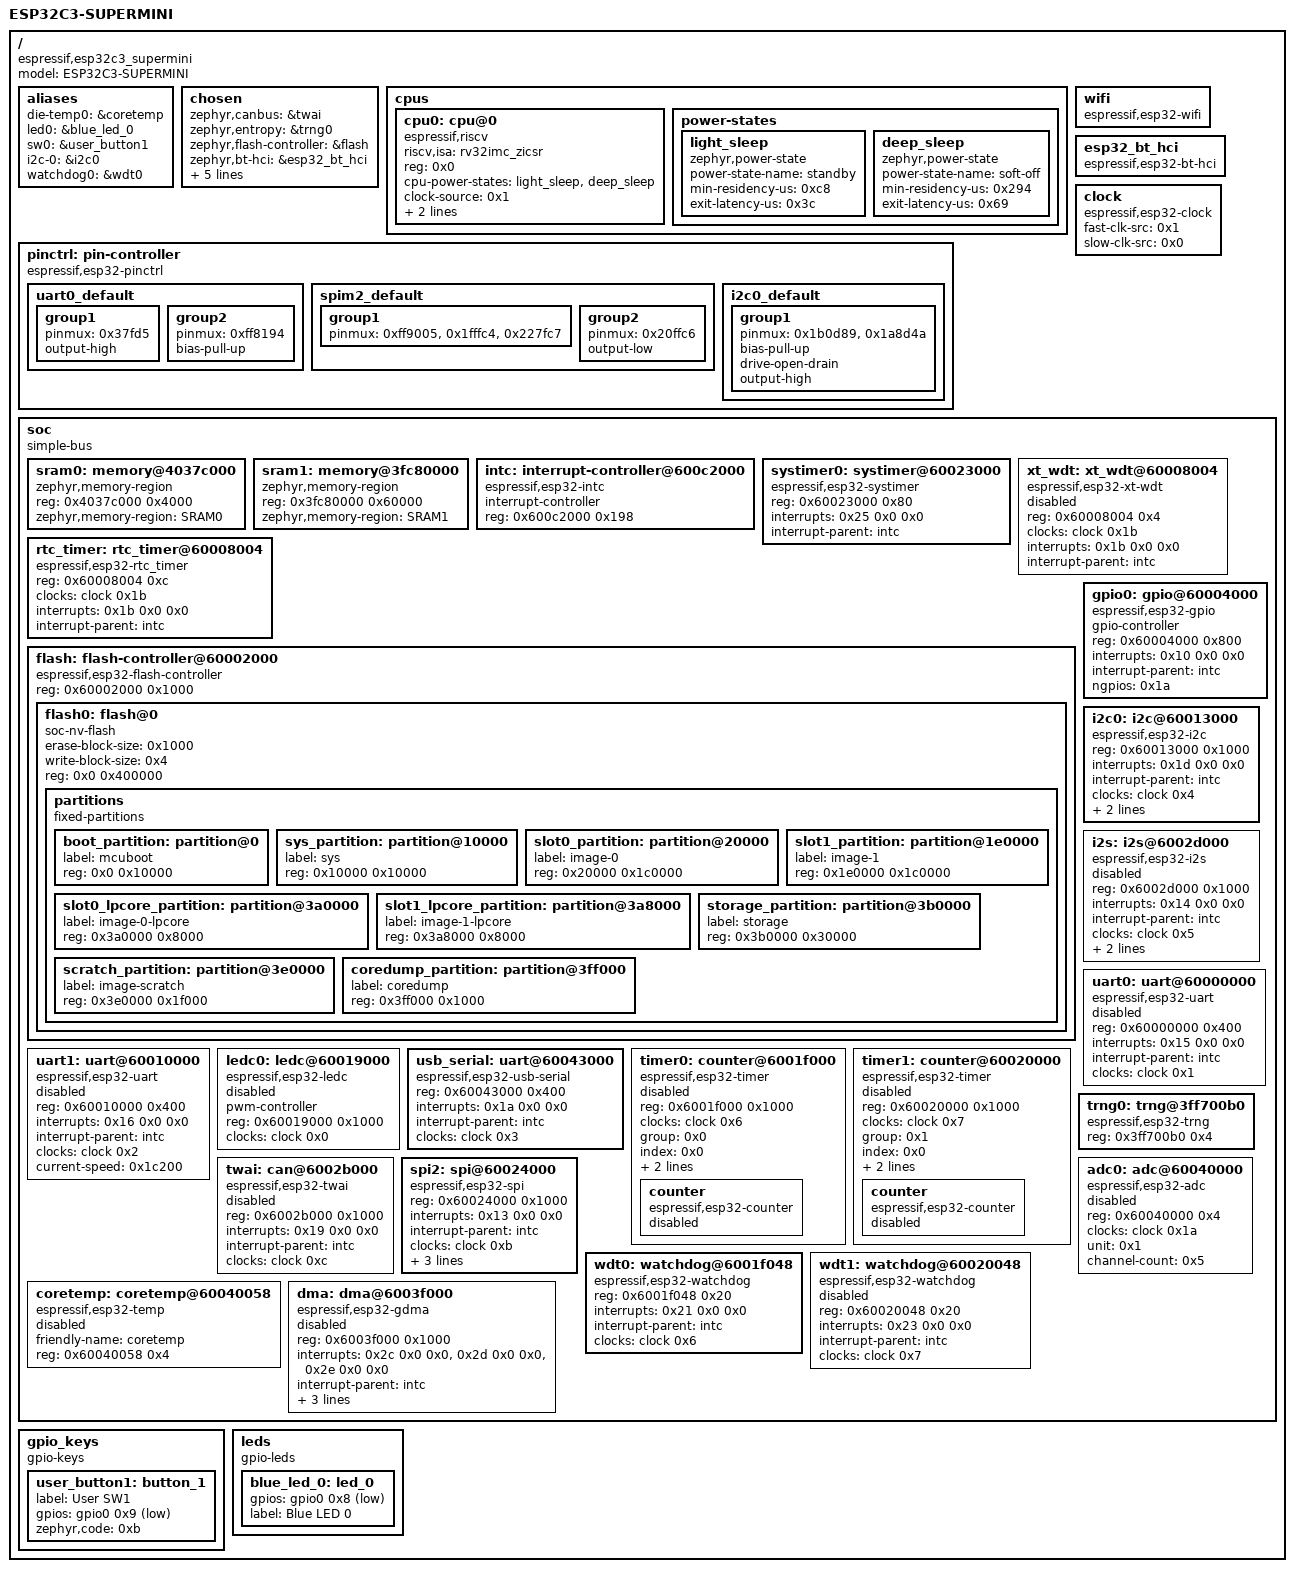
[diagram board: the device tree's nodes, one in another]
/dts-v1/;

/* node '/' defined in zephyr\dts\riscv\espressif\esp32c3\esp32c3_common.dtsi:15 */
/ {
	#address-cells = < 0x1 >;                   /* in zephyr\dts\riscv\espressif\esp32c3\esp32c3_common.dtsi:16 */
	#size-cells = < 0x1 >;                      /* in zephyr\dts\riscv\espressif\esp32c3\esp32c3_common.dtsi:17 */
	model = "ESP32C3-SUPERMINI";                /* in zephyr\boards\others\esp32c3_supermini\esp32c3_supermini.dts:15 */
	compatible = "espressif,esp32c3_supermini"; /* in zephyr\boards\others\esp32c3_supermini\esp32c3_supermini.dts:16 */

	/* node '/aliases' defined in zephyr\dts\riscv\espressif\esp32c3\esp32c3_common.dtsi:19 */
	aliases {
		die-temp0 = &coretemp; /* in zephyr\dts\riscv\espressif\esp32c3\esp32c3_common.dtsi:20 */
		led0 = &blue_led_0;    /* in zephyr\boards\others\esp32c3_supermini\esp32c3_supermini.dts:27 */
		sw0 = &user_button1;   /* in zephyr\boards\others\esp32c3_supermini\esp32c3_supermini.dts:28 */
		i2c-0 = &i2c0;         /* in zephyr\boards\others\esp32c3_supermini\esp32c3_supermini.dts:29 */
		watchdog0 = &wdt0;     /* in zephyr\boards\others\esp32c3_supermini\esp32c3_supermini.dts:30 */
	};

	/* node '/chosen' defined in zephyr\dts\riscv\espressif\esp32c3\esp32c3_common.dtsi:23 */
	chosen {
		zephyr,canbus = &twai;                    /* in zephyr\dts\riscv\espressif\esp32c3\esp32c3_common.dtsi:24 */
		zephyr,entropy = &trng0;                  /* in zephyr\dts\riscv\espressif\esp32c3\esp32c3_common.dtsi:25 */
		zephyr,flash-controller = &flash;         /* in zephyr\dts\riscv\espressif\esp32c3\esp32c3_common.dtsi:26 */
		zephyr,bt-hci = &esp32_bt_hci;            /* in zephyr\dts\riscv\espressif\esp32c3\esp32c3_common.dtsi:27 */
		zephyr,sram = &sram1;                     /* in zephyr\boards\others\esp32c3_supermini\esp32c3_supermini.dts:19 */
		zephyr,console = &usb_serial;             /* in zephyr\boards\others\esp32c3_supermini\esp32c3_supermini.dts:20 */
		zephyr,shell-uart = &usb_serial;          /* in zephyr\boards\others\esp32c3_supermini\esp32c3_supermini.dts:21 */
		zephyr,flash = &flash0;                   /* in zephyr\boards\others\esp32c3_supermini\esp32c3_supermini.dts:22 */
		zephyr,code-partition = &slot0_partition; /* in zephyr\boards\others\esp32c3_supermini\esp32c3_supermini.dts:23 */
	};

	/* node '/cpus' defined in zephyr\dts\riscv\espressif\esp32c3\esp32c3_common.dtsi:30 */
	cpus {
		#address-cells = < 0x1 >; /* in zephyr\dts\riscv\espressif\esp32c3\esp32c3_common.dtsi:31 */
		#size-cells = < 0x0 >;    /* in zephyr\dts\riscv\espressif\esp32c3\esp32c3_common.dtsi:32 */

		/* node '/cpus/cpu@0' defined in zephyr\dts\riscv\espressif\esp32c3\esp32c3_common.dtsi:34 */
		cpu0: cpu@0 {
			device_type = "cpu";                             /* in zephyr\dts\riscv\espressif\esp32c3\esp32c3_common.dtsi:35 */
			compatible = "espressif,riscv",
			             "riscv";                            /* in zephyr\dts\riscv\espressif\esp32c3\esp32c3_common.dtsi:36 */
			riscv,isa = "rv32imc_zicsr";                     /* in zephyr\dts\riscv\espressif\esp32c3\esp32c3_common.dtsi:37 */
			reg = < 0x0 >;                                   /* in zephyr\dts\riscv\espressif\esp32c3\esp32c3_common.dtsi:38 */
			cpu-power-states = < &light_sleep &deep_sleep >; /* in zephyr\dts\riscv\espressif\esp32c3\esp32c3_common.dtsi:39 */
			clock-source = < 0x1 >;                          /* in zephyr\dts\riscv\espressif\esp32c3\esp32c3_common.dtsi:40 */
			clock-frequency = < 0x9896800 >;                 /* in zephyr\dts\riscv\espressif\esp32c3\esp32c3_common.dtsi:41 */
			xtal-freq = < 0x2625a00 >;                       /* in zephyr\dts\riscv\espressif\esp32c3\esp32c3_common.dtsi:42 */
		};

		/* node '/cpus/power-states' defined in zephyr\dts\riscv\espressif\esp32c3\esp32c3_common.dtsi:45 */
		power-states {

			/* node '/cpus/power-states/light_sleep' defined in zephyr\dts\riscv\espressif\esp32c3\esp32c3_common.dtsi:46 */
			light_sleep: light_sleep {
				compatible = "zephyr,power-state"; /* in zephyr\dts\riscv\espressif\esp32c3\esp32c3_common.dtsi:47 */
				power-state-name = "standby";      /* in zephyr\dts\riscv\espressif\esp32c3\esp32c3_common.dtsi:48 */
				min-residency-us = < 0xc8 >;       /* in zephyr\dts\riscv\espressif\esp32c3\esp32c3_common.dtsi:49 */
				exit-latency-us = < 0x3c >;        /* in zephyr\dts\riscv\espressif\esp32c3\esp32c3_common.dtsi:50 */
				phandle = < 0x1 >;                 /* in zephyr\dts\riscv\espressif\esp32c3\esp32c3_common.dtsi:39 */
			};

			/* node '/cpus/power-states/deep_sleep' defined in zephyr\dts\riscv\espressif\esp32c3\esp32c3_common.dtsi:53 */
			deep_sleep: deep_sleep {
				compatible = "zephyr,power-state"; /* in zephyr\dts\riscv\espressif\esp32c3\esp32c3_common.dtsi:54 */
				power-state-name = "soft-off";     /* in zephyr\dts\riscv\espressif\esp32c3\esp32c3_common.dtsi:55 */
				min-residency-us = < 0x294 >;      /* in zephyr\dts\riscv\espressif\esp32c3\esp32c3_common.dtsi:56 */
				exit-latency-us = < 0x69 >;        /* in zephyr\dts\riscv\espressif\esp32c3\esp32c3_common.dtsi:57 */
				phandle = < 0x2 >;                 /* in zephyr\dts\riscv\espressif\esp32c3\esp32c3_common.dtsi:39 */
			};
		};
	};

	/* node '/pin-controller' defined in zephyr\dts\riscv\espressif\esp32c3\esp32c3_common.dtsi:62 */
	pinctrl: pin-controller {
		compatible = "espressif,esp32-pinctrl"; /* in zephyr\dts\riscv\espressif\esp32c3\esp32c3_common.dtsi:63 */
		status = "okay";                        /* in zephyr\dts\riscv\espressif\esp32c3\esp32c3_common.dtsi:64 */

		/* node '/pin-controller/uart0_default' defined in zephyr\boards\others\esp32c3_supermini\esp32c3_supermini-pinctrl.dtsi:12 */
		uart0_default: uart0_default {

			/* node '/pin-controller/uart0_default/group1' defined in zephyr\boards\others\esp32c3_supermini\esp32c3_supermini-pinctrl.dtsi:13 */
			group1 {
				pinmux = < 0x37fd5 >; /* in zephyr\boards\others\esp32c3_supermini\esp32c3_supermini-pinctrl.dtsi:14 */
				output-high;          /* in zephyr\boards\others\esp32c3_supermini\esp32c3_supermini-pinctrl.dtsi:15 */
			};

			/* node '/pin-controller/uart0_default/group2' defined in zephyr\boards\others\esp32c3_supermini\esp32c3_supermini-pinctrl.dtsi:17 */
			group2 {
				pinmux = < 0xff8194 >; /* in zephyr\boards\others\esp32c3_supermini\esp32c3_supermini-pinctrl.dtsi:18 */
				bias-pull-up;          /* in zephyr\boards\others\esp32c3_supermini\esp32c3_supermini-pinctrl.dtsi:19 */
			};
		};

		/* node '/pin-controller/spim2_default' defined in zephyr\boards\others\esp32c3_supermini\esp32c3_supermini-pinctrl.dtsi:23 */
		spim2_default: spim2_default {
			phandle = < 0x7 >; /* in zephyr\boards\others\esp32c3_supermini\esp32c3_supermini.dts:56 */

			/* node '/pin-controller/spim2_default/group1' defined in zephyr\boards\others\esp32c3_supermini\esp32c3_supermini-pinctrl.dtsi:24 */
			group1 {
				pinmux = < 0xff9005 >,
				         < 0x1fffc4 >,
				         < 0x227fc7 >; /* in zephyr\boards\others\esp32c3_supermini\esp32c3_supermini-pinctrl.dtsi:25 */
			};

			/* node '/pin-controller/spim2_default/group2' defined in zephyr\boards\others\esp32c3_supermini\esp32c3_supermini-pinctrl.dtsi:29 */
			group2 {
				pinmux = < 0x20ffc6 >; /* in zephyr\boards\others\esp32c3_supermini\esp32c3_supermini-pinctrl.dtsi:30 */
				output-low;            /* in zephyr\boards\others\esp32c3_supermini\esp32c3_supermini-pinctrl.dtsi:31 */
			};
		};

		/* node '/pin-controller/i2c0_default' defined in zephyr\boards\others\esp32c3_supermini\esp32c3_supermini-pinctrl.dtsi:35 */
		i2c0_default: i2c0_default {
			phandle = < 0x5 >; /* in zephyr\boards\others\esp32c3_supermini\esp32c3_supermini.dts:69 */

			/* node '/pin-controller/i2c0_default/group1' defined in zephyr\boards\others\esp32c3_supermini\esp32c3_supermini-pinctrl.dtsi:36 */
			group1 {
				pinmux = < 0x1b0d89 >,
				         < 0x1a8d4a >; /* in zephyr\boards\others\esp32c3_supermini\esp32c3_supermini-pinctrl.dtsi:37 */
				bias-pull-up;          /* in zephyr\boards\others\esp32c3_supermini\esp32c3_supermini-pinctrl.dtsi:39 */
				drive-open-drain;      /* in zephyr\boards\others\esp32c3_supermini\esp32c3_supermini-pinctrl.dtsi:40 */
				output-high;           /* in zephyr\boards\others\esp32c3_supermini\esp32c3_supermini-pinctrl.dtsi:41 */
			};
		};
	};

	/* node '/wifi' defined in zephyr\dts\riscv\espressif\esp32c3\esp32c3_common.dtsi:67 */
	wifi: wifi {
		compatible = "espressif,esp32-wifi"; /* in zephyr\dts\riscv\espressif\esp32c3\esp32c3_common.dtsi:68 */
		status = "okay";                     /* in zephyr\boards\others\esp32c3_supermini\esp32c3_supermini.dts:94 */
	};

	/* node '/esp32_bt_hci' defined in zephyr\dts\riscv\espressif\esp32c3\esp32c3_common.dtsi:72 */
	esp32_bt_hci: esp32_bt_hci {
		compatible = "espressif,esp32-bt-hci"; /* in zephyr\dts\riscv\espressif\esp32c3\esp32c3_common.dtsi:73 */
		status = "okay";                       /* in zephyr\boards\others\esp32c3_supermini\esp32c3_supermini.dts:90 */
	};

	/* node '/clock' defined in zephyr\dts\riscv\espressif\esp32c3\esp32c3_common.dtsi:77 */
	clock: clock {
		compatible = "espressif,esp32-clock"; /* in zephyr\dts\riscv\espressif\esp32c3\esp32c3_common.dtsi:78 */
		fast-clk-src = < 0x1 >;               /* in zephyr\dts\riscv\espressif\esp32c3\esp32c3_common.dtsi:79 */
		slow-clk-src = < 0x0 >;               /* in zephyr\dts\riscv\espressif\esp32c3\esp32c3_common.dtsi:80 */
		#clock-cells = < 0x1 >;               /* in zephyr\dts\riscv\espressif\esp32c3\esp32c3_common.dtsi:81 */
		status = "okay";                      /* in zephyr\dts\riscv\espressif\esp32c3\esp32c3_common.dtsi:82 */
		phandle = < 0x4 >;                    /* in zephyr\dts\riscv\espressif\esp32c3\esp32c3_common.dtsi:123 */
	};

	/* node '/soc' defined in zephyr\dts\riscv\espressif\esp32c3\esp32c3_common.dtsi:85 */
	soc {
		#address-cells = < 0x1 >;  /* in zephyr\dts\riscv\espressif\esp32c3\esp32c3_common.dtsi:86 */
		#size-cells = < 0x1 >;     /* in zephyr\dts\riscv\espressif\esp32c3\esp32c3_common.dtsi:87 */
		compatible = "simple-bus"; /* in zephyr\dts\riscv\espressif\esp32c3\esp32c3_common.dtsi:88 */
		ranges;                    /* in zephyr\dts\riscv\espressif\esp32c3\esp32c3_common.dtsi:89 */

		/* node '/soc/memory@4037c000' defined in zephyr\dts\riscv\espressif\esp32c3\esp32c3_common.dtsi:91 */
		sram0: memory@4037c000 {
			compatible = "zephyr,memory-region",
			             "mmio-sram";            /* in zephyr\dts\riscv\espressif\esp32c3\esp32c3_common.dtsi:92 */
			reg = < 0x4037c000 0x4000 >;         /* in zephyr\dts\riscv\espressif\esp32c3\esp32c3_common.dtsi:93 */
			zephyr,memory-region = "SRAM0";      /* in zephyr\dts\riscv\espressif\esp32c3\esp32c3_common.dtsi:94 */
		};

		/* node '/soc/memory@3fc80000' defined in zephyr\dts\riscv\espressif\esp32c3\esp32c3_common.dtsi:97 */
		sram1: memory@3fc80000 {
			compatible = "zephyr,memory-region",
			             "mmio-sram";            /* in zephyr\dts\riscv\espressif\esp32c3\esp32c3_common.dtsi:98 */
			reg = < 0x3fc80000 0x60000 >;        /* in zephyr\dts\riscv\espressif\esp32c3\esp32c3_common.dtsi:99 */
			zephyr,memory-region = "SRAM1";      /* in zephyr\dts\riscv\espressif\esp32c3\esp32c3_common.dtsi:100 */
		};

		/* node '/soc/interrupt-controller@600c2000' defined in zephyr\dts\riscv\espressif\esp32c3\esp32c3_common.dtsi:103 */
		intc: interrupt-controller@600c2000 {
			compatible = "espressif,esp32-intc"; /* in zephyr\dts\riscv\espressif\esp32c3\esp32c3_common.dtsi:104 */
			#address-cells = < 0x0 >;            /* in zephyr\dts\riscv\espressif\esp32c3\esp32c3_common.dtsi:105 */
			#interrupt-cells = < 0x3 >;          /* in zephyr\dts\riscv\espressif\esp32c3\esp32c3_common.dtsi:106 */
			interrupt-controller;                /* in zephyr\dts\riscv\espressif\esp32c3\esp32c3_common.dtsi:107 */
			reg = < 0x600c2000 0x198 >;          /* in zephyr\dts\riscv\espressif\esp32c3\esp32c3_common.dtsi:108 */
			status = "okay";                     /* in zephyr\dts\riscv\espressif\esp32c3\esp32c3_common.dtsi:109 */
			phandle = < 0x3 >;                   /* in zephyr\dts\riscv\espressif\esp32c3\esp32c3_common.dtsi:116 */
		};

		/* node '/soc/systimer@60023000' defined in zephyr\dts\riscv\espressif\esp32c3\esp32c3_common.dtsi:112 */
		systimer0: systimer@60023000 {
			compatible = "espressif,esp32-systimer"; /* in zephyr\dts\riscv\espressif\esp32c3\esp32c3_common.dtsi:113 */
			reg = < 0x60023000 0x80 >;               /* in zephyr\dts\riscv\espressif\esp32c3\esp32c3_common.dtsi:114 */
			interrupts = < 0x25 0x0 0x0 >;           /* in zephyr\dts\riscv\espressif\esp32c3\esp32c3_common.dtsi:115 */
			interrupt-parent = < &intc >;            /* in zephyr\dts\riscv\espressif\esp32c3\esp32c3_common.dtsi:116 */
			status = "okay";                         /* in zephyr\dts\riscv\espressif\esp32c3\esp32c3_common.dtsi:117 */
		};

		/* node '/soc/xt_wdt@60008004' defined in zephyr\dts\riscv\espressif\esp32c3\esp32c3_common.dtsi:120 */
		xt_wdt: xt_wdt@60008004 {
			compatible = "espressif,esp32-xt-wdt"; /* in zephyr\dts\riscv\espressif\esp32c3\esp32c3_common.dtsi:121 */
			reg = < 0x60008004 0x4 >;              /* in zephyr\dts\riscv\espressif\esp32c3\esp32c3_common.dtsi:122 */
			clocks = < &clock 0x1b >;              /* in zephyr\dts\riscv\espressif\esp32c3\esp32c3_common.dtsi:123 */
			interrupts = < 0x1b 0x0 0x0 >;         /* in zephyr\dts\riscv\espressif\esp32c3\esp32c3_common.dtsi:124 */
			interrupt-parent = < &intc >;          /* in zephyr\dts\riscv\espressif\esp32c3\esp32c3_common.dtsi:125 */
			status = "disabled";                   /* in zephyr\dts\riscv\espressif\esp32c3\esp32c3_common.dtsi:126 */
		};

		/* node '/soc/rtc_timer@60008004' defined in zephyr\dts\riscv\espressif\esp32c3\esp32c3_common.dtsi:129 */
		rtc_timer: rtc_timer@60008004 {
			reg = < 0x60008004 0xc >;                 /* in zephyr\dts\riscv\espressif\esp32c3\esp32c3_common.dtsi:130 */
			compatible = "espressif,esp32-rtc_timer"; /* in zephyr\dts\riscv\espressif\esp32c3\esp32c3_common.dtsi:131 */
			clocks = < &clock 0x1b >;                 /* in zephyr\dts\riscv\espressif\esp32c3\esp32c3_common.dtsi:132 */
			interrupts = < 0x1b 0x0 0x0 >;            /* in zephyr\dts\riscv\espressif\esp32c3\esp32c3_common.dtsi:133 */
			interrupt-parent = < &intc >;             /* in zephyr\dts\riscv\espressif\esp32c3\esp32c3_common.dtsi:134 */
			status = "okay";                          /* in zephyr\dts\riscv\espressif\esp32c3\esp32c3_common.dtsi:135 */
		};

		/* node '/soc/flash-controller@60002000' defined in zephyr\dts\riscv\espressif\esp32c3\esp32c3_common.dtsi:138 */
		flash: flash-controller@60002000 {
			compatible = "espressif,esp32-flash-controller"; /* in zephyr\dts\riscv\espressif\esp32c3\esp32c3_common.dtsi:139 */
			reg = < 0x60002000 0x1000 >;                     /* in zephyr\dts\riscv\espressif\esp32c3\esp32c3_common.dtsi:140 */
			#address-cells = < 0x1 >;                        /* in zephyr\dts\riscv\espressif\esp32c3\esp32c3_common.dtsi:142 */
			#size-cells = < 0x1 >;                           /* in zephyr\dts\riscv\espressif\esp32c3\esp32c3_common.dtsi:143 */

			/* node '/soc/flash-controller@60002000/flash@0' defined in zephyr\dts\riscv\espressif\esp32c3\esp32c3_common.dtsi:145 */
			flash0: flash@0 {
				compatible = "soc-nv-flash";   /* in zephyr\dts\riscv\espressif\esp32c3\esp32c3_common.dtsi:146 */
				erase-block-size = < 0x1000 >; /* in zephyr\dts\riscv\espressif\esp32c3\esp32c3_common.dtsi:147 */
				write-block-size = < 0x4 >;    /* in zephyr\dts\riscv\espressif\esp32c3\esp32c3_common.dtsi:148 */
				reg = < 0x0 0x400000 >;        /* in zephyr\dts\riscv\espressif\esp32c3\esp32c3_fx4.dtsi:11 */

				/* node '/soc/flash-controller@60002000/flash@0/partitions' defined in zephyr\dts\vendor\espressif\partitions_0x0_default_4M.dtsi:8 */
				partitions {
					compatible = "fixed-partitions"; /* in zephyr\dts\vendor\espressif\partitions_0x0_default_4M.dtsi:9 */
					#address-cells = < 0x1 >;        /* in zephyr\dts\vendor\espressif\partitions_0x0_default_4M.dtsi:10 */
					#size-cells = < 0x1 >;           /* in zephyr\dts\vendor\espressif\partitions_0x0_default_4M.dtsi:11 */

					/* node '/soc/flash-controller@60002000/flash@0/partitions/partition@0' defined in zephyr\dts\vendor\espressif\partitions_0x0_default_4M.dtsi:13 */
					boot_partition: partition@0 {
						label = "mcuboot";     /* in zephyr\dts\vendor\espressif\partitions_0x0_default_4M.dtsi:14 */
						reg = < 0x0 0x10000 >; /* in zephyr\dts\vendor\espressif\partitions_0x0_default_4M.dtsi:15 */
					};

					/* node '/soc/flash-controller@60002000/flash@0/partitions/partition@10000' defined in zephyr\dts\vendor\espressif\partitions_0x0_default_4M.dtsi:18 */
					sys_partition: partition@10000 {
						label = "sys";             /* in zephyr\dts\vendor\espressif\partitions_0x0_default_4M.dtsi:19 */
						reg = < 0x10000 0x10000 >; /* in zephyr\dts\vendor\espressif\partitions_0x0_default_4M.dtsi:20 */
					};

					/* node '/soc/flash-controller@60002000/flash@0/partitions/partition@20000' defined in zephyr\dts\vendor\espressif\partitions_0x0_default_4M.dtsi:23 */
					slot0_partition: partition@20000 {
						label = "image-0";          /* in zephyr\dts\vendor\espressif\partitions_0x0_default_4M.dtsi:24 */
						reg = < 0x20000 0x1c0000 >; /* in zephyr\dts\vendor\espressif\partitions_0x0_default_4M.dtsi:25 */
					};

					/* node '/soc/flash-controller@60002000/flash@0/partitions/partition@1e0000' defined in zephyr\dts\vendor\espressif\partitions_0x0_default_4M.dtsi:28 */
					slot1_partition: partition@1e0000 {
						label = "image-1";           /* in zephyr\dts\vendor\espressif\partitions_0x0_default_4M.dtsi:29 */
						reg = < 0x1e0000 0x1c0000 >; /* in zephyr\dts\vendor\espressif\partitions_0x0_default_4M.dtsi:30 */
					};

					/* node '/soc/flash-controller@60002000/flash@0/partitions/partition@3a0000' defined in zephyr\dts\vendor\espressif\partitions_0x0_default_4M.dtsi:33 */
					slot0_lpcore_partition: partition@3a0000 {
						label = "image-0-lpcore";  /* in zephyr\dts\vendor\espressif\partitions_0x0_default_4M.dtsi:34 */
						reg = < 0x3a0000 0x8000 >; /* in zephyr\dts\vendor\espressif\partitions_0x0_default_4M.dtsi:35 */
					};

					/* node '/soc/flash-controller@60002000/flash@0/partitions/partition@3a8000' defined in zephyr\dts\vendor\espressif\partitions_0x0_default_4M.dtsi:38 */
					slot1_lpcore_partition: partition@3a8000 {
						label = "image-1-lpcore";  /* in zephyr\dts\vendor\espressif\partitions_0x0_default_4M.dtsi:39 */
						reg = < 0x3a8000 0x8000 >; /* in zephyr\dts\vendor\espressif\partitions_0x0_default_4M.dtsi:40 */
					};

					/* node '/soc/flash-controller@60002000/flash@0/partitions/partition@3b0000' defined in zephyr\dts\vendor\espressif\partitions_0x0_default_4M.dtsi:43 */
					storage_partition: partition@3b0000 {
						label = "storage";          /* in zephyr\dts\vendor\espressif\partitions_0x0_default_4M.dtsi:44 */
						reg = < 0x3b0000 0x30000 >; /* in zephyr\dts\vendor\espressif\partitions_0x0_default_4M.dtsi:45 */
					};

					/* node '/soc/flash-controller@60002000/flash@0/partitions/partition@3e0000' defined in zephyr\dts\vendor\espressif\partitions_0x0_default_4M.dtsi:48 */
					scratch_partition: partition@3e0000 {
						label = "image-scratch";    /* in zephyr\dts\vendor\espressif\partitions_0x0_default_4M.dtsi:49 */
						reg = < 0x3e0000 0x1f000 >; /* in zephyr\dts\vendor\espressif\partitions_0x0_default_4M.dtsi:50 */
					};

					/* node '/soc/flash-controller@60002000/flash@0/partitions/partition@3ff000' defined in zephyr\dts\vendor\espressif\partitions_0x0_default_4M.dtsi:53 */
					coredump_partition: partition@3ff000 {
						label = "coredump";        /* in zephyr\dts\vendor\espressif\partitions_0x0_default_4M.dtsi:54 */
						reg = < 0x3ff000 0x1000 >; /* in zephyr\dts\vendor\espressif\partitions_0x0_default_4M.dtsi:55 */
					};
				};
			};
		};

		/* node '/soc/gpio@60004000' defined in zephyr\dts\riscv\espressif\esp32c3\esp32c3_common.dtsi:153 */
		gpio0: gpio@60004000 {
			compatible = "espressif,esp32-gpio"; /* in zephyr\dts\riscv\espressif\esp32c3\esp32c3_common.dtsi:154 */
			gpio-controller;                     /* in zephyr\dts\riscv\espressif\esp32c3\esp32c3_common.dtsi:155 */
			#gpio-cells = < 0x2 >;               /* in zephyr\dts\riscv\espressif\esp32c3\esp32c3_common.dtsi:156 */
			reg = < 0x60004000 0x800 >;          /* in zephyr\dts\riscv\espressif\esp32c3\esp32c3_common.dtsi:157 */
			interrupts = < 0x10 0x0 0x0 >;       /* in zephyr\dts\riscv\espressif\esp32c3\esp32c3_common.dtsi:158 */
			interrupt-parent = < &intc >;        /* in zephyr\dts\riscv\espressif\esp32c3\esp32c3_common.dtsi:159 */
			ngpios = < 0x1a >;                   /* in zephyr\dts\riscv\espressif\esp32c3\esp32c3_common.dtsi:165 */
			status = "okay";                     /* in zephyr\boards\others\esp32c3_supermini\esp32c3_supermini.dts:78 */
			phandle = < 0x8 >;                   /* in zephyr\boards\others\esp32c3_supermini\esp32c3_supermini.dts:37 */
		};

		/* node '/soc/i2c@60013000' defined in zephyr\dts\riscv\espressif\esp32c3\esp32c3_common.dtsi:168 */
		i2c0: i2c@60013000 {
			compatible = "espressif,esp32-i2c"; /* in zephyr\dts\riscv\espressif\esp32c3\esp32c3_common.dtsi:169 */
			#address-cells = < 0x1 >;           /* in zephyr\dts\riscv\espressif\esp32c3\esp32c3_common.dtsi:170 */
			#size-cells = < 0x0 >;              /* in zephyr\dts\riscv\espressif\esp32c3\esp32c3_common.dtsi:171 */
			reg = < 0x60013000 0x1000 >;        /* in zephyr\dts\riscv\espressif\esp32c3\esp32c3_common.dtsi:172 */
			interrupts = < 0x1d 0x0 0x0 >;      /* in zephyr\dts\riscv\espressif\esp32c3\esp32c3_common.dtsi:173 */
			interrupt-parent = < &intc >;       /* in zephyr\dts\riscv\espressif\esp32c3\esp32c3_common.dtsi:174 */
			clocks = < &clock 0x4 >;            /* in zephyr\dts\riscv\espressif\esp32c3\esp32c3_common.dtsi:175 */
			status = "okay";                    /* in zephyr\boards\others\esp32c3_supermini\esp32c3_supermini.dts:67 */
			clock-frequency = < 0x186a0 >;      /* in zephyr\boards\others\esp32c3_supermini\esp32c3_supermini.dts:68 */
			pinctrl-0 = < &i2c0_default >;      /* in zephyr\boards\others\esp32c3_supermini\esp32c3_supermini.dts:69 */
			pinctrl-names = "default";          /* in zephyr\boards\others\esp32c3_supermini\esp32c3_supermini.dts:70 */
		};

		/* node '/soc/i2s@6002d000' defined in zephyr\dts\riscv\espressif\esp32c3\esp32c3_common.dtsi:179 */
		i2s: i2s@6002d000 {
			compatible = "espressif,esp32-i2s"; /* in zephyr\dts\riscv\espressif\esp32c3\esp32c3_common.dtsi:180 */
			#address-cells = < 0x1 >;           /* in zephyr\dts\riscv\espressif\esp32c3\esp32c3_common.dtsi:181 */
			#size-cells = < 0x0 >;              /* in zephyr\dts\riscv\espressif\esp32c3\esp32c3_common.dtsi:182 */
			reg = < 0x6002d000 0x1000 >;        /* in zephyr\dts\riscv\espressif\esp32c3\esp32c3_common.dtsi:183 */
			interrupts = < 0x14 0x0 0x0 >;      /* in zephyr\dts\riscv\espressif\esp32c3\esp32c3_common.dtsi:184 */
			interrupt-parent = < &intc >;       /* in zephyr\dts\riscv\espressif\esp32c3\esp32c3_common.dtsi:185 */
			clocks = < &clock 0x5 >;            /* in zephyr\dts\riscv\espressif\esp32c3\esp32c3_common.dtsi:186 */
			dmas = < &dma 0x2 >,
			       < &dma 0x3 >;                /* in zephyr\dts\riscv\espressif\esp32c3\esp32c3_common.dtsi:187 */
			dma-names = "rx",
			            "tx";                   /* in zephyr\dts\riscv\espressif\esp32c3\esp32c3_common.dtsi:188 */
			unit = < 0x0 >;                     /* in zephyr\dts\riscv\espressif\esp32c3\esp32c3_common.dtsi:189 */
			status = "disabled";                /* in zephyr\dts\riscv\espressif\esp32c3\esp32c3_common.dtsi:190 */
		};

		/* node '/soc/uart@60000000' defined in zephyr\dts\riscv\espressif\esp32c3\esp32c3_common.dtsi:193 */
		uart0: uart@60000000 {
			compatible = "espressif,esp32-uart"; /* in zephyr\dts\riscv\espressif\esp32c3\esp32c3_common.dtsi:194 */
			reg = < 0x60000000 0x400 >;          /* in zephyr\dts\riscv\espressif\esp32c3\esp32c3_common.dtsi:195 */
			interrupts = < 0x15 0x0 0x0 >;       /* in zephyr\dts\riscv\espressif\esp32c3\esp32c3_common.dtsi:197 */
			interrupt-parent = < &intc >;        /* in zephyr\dts\riscv\espressif\esp32c3\esp32c3_common.dtsi:198 */
			clocks = < &clock 0x1 >;             /* in zephyr\dts\riscv\espressif\esp32c3\esp32c3_common.dtsi:199 */
			status = "disabled";                 /* in zephyr\boards\others\esp32c3_supermini\esp32c3_supermini.dts:86 */
		};

		/* node '/soc/uart@60010000' defined in zephyr\dts\riscv\espressif\esp32c3\esp32c3_common.dtsi:202 */
		uart1: uart@60010000 {
			compatible = "espressif,esp32-uart"; /* in zephyr\dts\riscv\espressif\esp32c3\esp32c3_common.dtsi:203 */
			reg = < 0x60010000 0x400 >;          /* in zephyr\dts\riscv\espressif\esp32c3\esp32c3_common.dtsi:204 */
			status = "disabled";                 /* in zephyr\dts\riscv\espressif\esp32c3\esp32c3_common.dtsi:205 */
			interrupts = < 0x16 0x0 0x0 >;       /* in zephyr\dts\riscv\espressif\esp32c3\esp32c3_common.dtsi:206 */
			interrupt-parent = < &intc >;        /* in zephyr\dts\riscv\espressif\esp32c3\esp32c3_common.dtsi:207 */
			clocks = < &clock 0x2 >;             /* in zephyr\dts\riscv\espressif\esp32c3\esp32c3_common.dtsi:208 */
			current-speed = < 0x1c200 >;         /* in zephyr\dts\riscv\espressif\esp32c3\esp32c3_common.dtsi:209 */
		};

		/* node '/soc/ledc@60019000' defined in zephyr\dts\riscv\espressif\esp32c3\esp32c3_common.dtsi:212 */
		ledc0: ledc@60019000 {
			compatible = "espressif,esp32-ledc"; /* in zephyr\dts\riscv\espressif\esp32c3\esp32c3_common.dtsi:213 */
			pwm-controller;                      /* in zephyr\dts\riscv\espressif\esp32c3\esp32c3_common.dtsi:214 */
			#pwm-cells = < 0x3 >;                /* in zephyr\dts\riscv\espressif\esp32c3\esp32c3_common.dtsi:215 */
			reg = < 0x60019000 0x1000 >;         /* in zephyr\dts\riscv\espressif\esp32c3\esp32c3_common.dtsi:216 */
			clocks = < &clock 0x0 >;             /* in zephyr\dts\riscv\espressif\esp32c3\esp32c3_common.dtsi:217 */
			status = "disabled";                 /* in zephyr\dts\riscv\espressif\esp32c3\esp32c3_common.dtsi:218 */
		};

		/* node '/soc/uart@60043000' defined in zephyr\dts\riscv\espressif\esp32c3\esp32c3_common.dtsi:221 */
		usb_serial: uart@60043000 {
			compatible = "espressif,esp32-usb-serial"; /* in zephyr\dts\riscv\espressif\esp32c3\esp32c3_common.dtsi:222 */
			reg = < 0x60043000 0x400 >;                /* in zephyr\dts\riscv\espressif\esp32c3\esp32c3_common.dtsi:223 */
			interrupts = < 0x1a 0x0 0x0 >;             /* in zephyr\dts\riscv\espressif\esp32c3\esp32c3_common.dtsi:225 */
			interrupt-parent = < &intc >;              /* in zephyr\dts\riscv\espressif\esp32c3\esp32c3_common.dtsi:226 */
			clocks = < &clock 0x3 >;                   /* in zephyr\dts\riscv\espressif\esp32c3\esp32c3_common.dtsi:227 */
			status = "okay";                           /* in zephyr\boards\others\esp32c3_supermini\esp32c3_supermini.dts:62 */
		};

		/* node '/soc/counter@6001f000' defined in zephyr\dts\riscv\espressif\esp32c3\esp32c3_common.dtsi:230 */
		timer0: counter@6001f000 {
			compatible = "espressif,esp32-timer"; /* in zephyr\dts\riscv\espressif\esp32c3\esp32c3_common.dtsi:231 */
			reg = < 0x6001f000 0x1000 >;          /* in zephyr\dts\riscv\espressif\esp32c3\esp32c3_common.dtsi:232 */
			clocks = < &clock 0x6 >;              /* in zephyr\dts\riscv\espressif\esp32c3\esp32c3_common.dtsi:233 */
			group = < 0x0 >;                      /* in zephyr\dts\riscv\espressif\esp32c3\esp32c3_common.dtsi:234 */
			index = < 0x0 >;                      /* in zephyr\dts\riscv\espressif\esp32c3\esp32c3_common.dtsi:235 */
			interrupts = < 0x20 0x0 0x0 >;        /* in zephyr\dts\riscv\espressif\esp32c3\esp32c3_common.dtsi:236 */
			interrupt-parent = < &intc >;         /* in zephyr\dts\riscv\espressif\esp32c3\esp32c3_common.dtsi:237 */
			status = "disabled";                  /* in zephyr\dts\riscv\espressif\esp32c3\esp32c3_common.dtsi:238 */

			/* node '/soc/counter@6001f000/counter' defined in zephyr\dts\riscv\espressif\esp32c3\esp32c3_common.dtsi:240 */
			counter {
				compatible = "espressif,esp32-counter"; /* in zephyr\dts\riscv\espressif\esp32c3\esp32c3_common.dtsi:241 */
				status = "disabled";                    /* in zephyr\dts\riscv\espressif\esp32c3\esp32c3_common.dtsi:242 */
			};
		};

		/* node '/soc/counter@60020000' defined in zephyr\dts\riscv\espressif\esp32c3\esp32c3_common.dtsi:246 */
		timer1: counter@60020000 {
			compatible = "espressif,esp32-timer"; /* in zephyr\dts\riscv\espressif\esp32c3\esp32c3_common.dtsi:247 */
			reg = < 0x60020000 0x1000 >;          /* in zephyr\dts\riscv\espressif\esp32c3\esp32c3_common.dtsi:248 */
			clocks = < &clock 0x7 >;              /* in zephyr\dts\riscv\espressif\esp32c3\esp32c3_common.dtsi:249 */
			group = < 0x1 >;                      /* in zephyr\dts\riscv\espressif\esp32c3\esp32c3_common.dtsi:250 */
			index = < 0x0 >;                      /* in zephyr\dts\riscv\espressif\esp32c3\esp32c3_common.dtsi:251 */
			interrupts = < 0x22 0x0 0x0 >;        /* in zephyr\dts\riscv\espressif\esp32c3\esp32c3_common.dtsi:252 */
			interrupt-parent = < &intc >;         /* in zephyr\dts\riscv\espressif\esp32c3\esp32c3_common.dtsi:253 */
			status = "disabled";                  /* in zephyr\dts\riscv\espressif\esp32c3\esp32c3_common.dtsi:254 */

			/* node '/soc/counter@60020000/counter' defined in zephyr\dts\riscv\espressif\esp32c3\esp32c3_common.dtsi:256 */
			counter {
				compatible = "espressif,esp32-counter"; /* in zephyr\dts\riscv\espressif\esp32c3\esp32c3_common.dtsi:257 */
				status = "disabled";                    /* in zephyr\dts\riscv\espressif\esp32c3\esp32c3_common.dtsi:258 */
			};
		};

		/* node '/soc/trng@3ff700b0' defined in zephyr\dts\riscv\espressif\esp32c3\esp32c3_common.dtsi:262 */
		trng0: trng@3ff700b0 {
			compatible = "espressif,esp32-trng"; /* in zephyr\dts\riscv\espressif\esp32c3\esp32c3_common.dtsi:263 */
			reg = < 0x3ff700b0 0x4 >;            /* in zephyr\dts\riscv\espressif\esp32c3\esp32c3_common.dtsi:264 */
			status = "okay";                     /* in zephyr\boards\others\esp32c3_supermini\esp32c3_supermini.dts:74 */
		};

		/* node '/soc/can@6002b000' defined in zephyr\dts\riscv\espressif\esp32c3\esp32c3_common.dtsi:268 */
		twai: can@6002b000 {
			compatible = "espressif,esp32-twai"; /* in zephyr\dts\riscv\espressif\esp32c3\esp32c3_common.dtsi:269 */
			reg = < 0x6002b000 0x1000 >;         /* in zephyr\dts\riscv\espressif\esp32c3\esp32c3_common.dtsi:270 */
			interrupts = < 0x19 0x0 0x0 >;       /* in zephyr\dts\riscv\espressif\esp32c3\esp32c3_common.dtsi:271 */
			interrupt-parent = < &intc >;        /* in zephyr\dts\riscv\espressif\esp32c3\esp32c3_common.dtsi:272 */
			clocks = < &clock 0xc >;             /* in zephyr\dts\riscv\espressif\esp32c3\esp32c3_common.dtsi:273 */
			status = "disabled";                 /* in zephyr\dts\riscv\espressif\esp32c3\esp32c3_common.dtsi:274 */
		};

		/* node '/soc/spi@60024000' defined in zephyr\dts\riscv\espressif\esp32c3\esp32c3_common.dtsi:277 */
		spi2: spi@60024000 {
			compatible = "espressif,esp32-spi"; /* in zephyr\dts\riscv\espressif\esp32c3\esp32c3_common.dtsi:278 */
			reg = < 0x60024000 0x1000 >;        /* in zephyr\dts\riscv\espressif\esp32c3\esp32c3_common.dtsi:279 */
			interrupts = < 0x13 0x0 0x0 >;      /* in zephyr\dts\riscv\espressif\esp32c3\esp32c3_common.dtsi:280 */
			interrupt-parent = < &intc >;       /* in zephyr\dts\riscv\espressif\esp32c3\esp32c3_common.dtsi:281 */
			clocks = < &clock 0xb >;            /* in zephyr\dts\riscv\espressif\esp32c3\esp32c3_common.dtsi:282 */
			dma-clk = < 0x18 >;                 /* in zephyr\dts\riscv\espressif\esp32c3\esp32c3_common.dtsi:283 */
			dma-host = < 0x0 >;                 /* in zephyr\dts\riscv\espressif\esp32c3\esp32c3_common.dtsi:284 */
			#address-cells = < 0x1 >;           /* in zephyr\boards\others\esp32c3_supermini\esp32c3_supermini.dts:53 */
			#size-cells = < 0x0 >;              /* in zephyr\boards\others\esp32c3_supermini\esp32c3_supermini.dts:54 */
			status = "okay";                    /* in zephyr\boards\others\esp32c3_supermini\esp32c3_supermini.dts:55 */
			pinctrl-0 = < &spim2_default >;     /* in zephyr\boards\others\esp32c3_supermini\esp32c3_supermini.dts:56 */
			pinctrl-names = "default";          /* in zephyr\boards\others\esp32c3_supermini\esp32c3_supermini.dts:57 */
		};

		/* node '/soc/watchdog@6001f048' defined in zephyr\dts\riscv\espressif\esp32c3\esp32c3_common.dtsi:288 */
		wdt0: watchdog@6001f048 {
			compatible = "espressif,esp32-watchdog"; /* in zephyr\dts\riscv\espressif\esp32c3\esp32c3_common.dtsi:289 */
			reg = < 0x6001f048 0x20 >;               /* in zephyr\dts\riscv\espressif\esp32c3\esp32c3_common.dtsi:290 */
			interrupts = < 0x21 0x0 0x0 >;           /* in zephyr\dts\riscv\espressif\esp32c3\esp32c3_common.dtsi:291 */
			interrupt-parent = < &intc >;            /* in zephyr\dts\riscv\espressif\esp32c3\esp32c3_common.dtsi:292 */
			clocks = < &clock 0x6 >;                 /* in zephyr\dts\riscv\espressif\esp32c3\esp32c3_common.dtsi:293 */
			status = "okay";                         /* in zephyr\boards\others\esp32c3_supermini\esp32c3_supermini.dts:82 */
		};

		/* node '/soc/watchdog@60020048' defined in zephyr\dts\riscv\espressif\esp32c3\esp32c3_common.dtsi:297 */
		wdt1: watchdog@60020048 {
			compatible = "espressif,esp32-watchdog"; /* in zephyr\dts\riscv\espressif\esp32c3\esp32c3_common.dtsi:298 */
			reg = < 0x60020048 0x20 >;               /* in zephyr\dts\riscv\espressif\esp32c3\esp32c3_common.dtsi:299 */
			interrupts = < 0x23 0x0 0x0 >;           /* in zephyr\dts\riscv\espressif\esp32c3\esp32c3_common.dtsi:300 */
			interrupt-parent = < &intc >;            /* in zephyr\dts\riscv\espressif\esp32c3\esp32c3_common.dtsi:301 */
			clocks = < &clock 0x7 >;                 /* in zephyr\dts\riscv\espressif\esp32c3\esp32c3_common.dtsi:302 */
			status = "disabled";                     /* in zephyr\dts\riscv\espressif\esp32c3\esp32c3_common.dtsi:303 */
		};

		/* node '/soc/coretemp@60040058' defined in zephyr\dts\riscv\espressif\esp32c3\esp32c3_common.dtsi:306 */
		coretemp: coretemp@60040058 {
			compatible = "espressif,esp32-temp"; /* in zephyr\dts\riscv\espressif\esp32c3\esp32c3_common.dtsi:307 */
			friendly-name = "coretemp";          /* in zephyr\dts\riscv\espressif\esp32c3\esp32c3_common.dtsi:308 */
			reg = < 0x60040058 0x4 >;            /* in zephyr\dts\riscv\espressif\esp32c3\esp32c3_common.dtsi:309 */
			status = "disabled";                 /* in zephyr\dts\riscv\espressif\esp32c3\esp32c3_common.dtsi:310 */
		};

		/* node '/soc/adc@60040000' defined in zephyr\dts\riscv\espressif\esp32c3\esp32c3_common.dtsi:313 */
		adc0: adc@60040000 {
			compatible = "espressif,esp32-adc"; /* in zephyr\dts\riscv\espressif\esp32c3\esp32c3_common.dtsi:314 */
			reg = < 0x60040000 0x4 >;           /* in zephyr\dts\riscv\espressif\esp32c3\esp32c3_common.dtsi:315 */
			clocks = < &clock 0x1a >;           /* in zephyr\dts\riscv\espressif\esp32c3\esp32c3_common.dtsi:316 */
			unit = < 0x1 >;                     /* in zephyr\dts\riscv\espressif\esp32c3\esp32c3_common.dtsi:317 */
			channel-count = < 0x5 >;            /* in zephyr\dts\riscv\espressif\esp32c3\esp32c3_common.dtsi:318 */
			#io-channel-cells = < 0x1 >;        /* in zephyr\dts\riscv\espressif\esp32c3\esp32c3_common.dtsi:319 */
			status = "disabled";                /* in zephyr\dts\riscv\espressif\esp32c3\esp32c3_common.dtsi:320 */
		};

		/* node '/soc/dma@6003f000' defined in zephyr\dts\riscv\espressif\esp32c3\esp32c3_common.dtsi:323 */
		dma: dma@6003f000 {
			compatible = "espressif,esp32-gdma"; /* in zephyr\dts\riscv\espressif\esp32c3\esp32c3_common.dtsi:324 */
			reg = < 0x6003f000 0x1000 >;         /* in zephyr\dts\riscv\espressif\esp32c3\esp32c3_common.dtsi:325 */
			#dma-cells = < 0x1 >;                /* in zephyr\dts\riscv\espressif\esp32c3\esp32c3_common.dtsi:326 */
			interrupts = < 0x2c 0x0 0x0 >,
			             < 0x2d 0x0 0x0 >,
			             < 0x2e 0x0 0x0 >;       /* in zephyr\dts\riscv\espressif\esp32c3\esp32c3_common.dtsi:327 */
			interrupt-parent = < &intc >;        /* in zephyr\dts\riscv\espressif\esp32c3\esp32c3_common.dtsi:331 */
			clocks = < &clock 0x18 >;            /* in zephyr\dts\riscv\espressif\esp32c3\esp32c3_common.dtsi:332 */
			dma-channels = < 0x6 >;              /* in zephyr\dts\riscv\espressif\esp32c3\esp32c3_common.dtsi:333 */
			dma-buf-addr-alignment = < 0x4 >;    /* in zephyr\dts\riscv\espressif\esp32c3\esp32c3_common.dtsi:334 */
			status = "disabled";                 /* in zephyr\dts\riscv\espressif\esp32c3\esp32c3_common.dtsi:335 */
			phandle = < 0x6 >;                   /* in zephyr\dts\riscv\espressif\esp32c3\esp32c3_common.dtsi:187 */
		};
	};

	/* node '/gpio_keys' defined in zephyr\boards\others\esp32c3_supermini\esp32c3_supermini.dts:33 */
	gpio_keys {
		compatible = "gpio-keys"; /* in zephyr\boards\others\esp32c3_supermini\esp32c3_supermini.dts:34 */

		/* node '/gpio_keys/button_1' defined in zephyr\boards\others\esp32c3_supermini\esp32c3_supermini.dts:35 */
		user_button1: button_1 {
			label = "User SW1";          /* in zephyr\boards\others\esp32c3_supermini\esp32c3_supermini.dts:36 */
			gpios = < &gpio0 0x9 0x11 >; /* in zephyr\boards\others\esp32c3_supermini\esp32c3_supermini.dts:37 */
			zephyr,code = < 0xb >;       /* in zephyr\boards\others\esp32c3_supermini\esp32c3_supermini.dts:38 */
		};
	};

	/* node '/leds' defined in zephyr\boards\others\esp32c3_supermini\esp32c3_supermini.dts:42 */
	leds {
		compatible = "gpio-leds"; /* in zephyr\boards\others\esp32c3_supermini\esp32c3_supermini.dts:43 */

		/* node '/leds/led_0' defined in zephyr\boards\others\esp32c3_supermini\esp32c3_supermini.dts:44 */
		blue_led_0: led_0 {
			gpios = < &gpio0 0x8 0x1 >; /* in zephyr\boards\others\esp32c3_supermini\esp32c3_supermini.dts:45 */
			label = "Blue LED 0";       /* in zephyr\boards\others\esp32c3_supermini\esp32c3_supermini.dts:46 */
		};
	};
};
